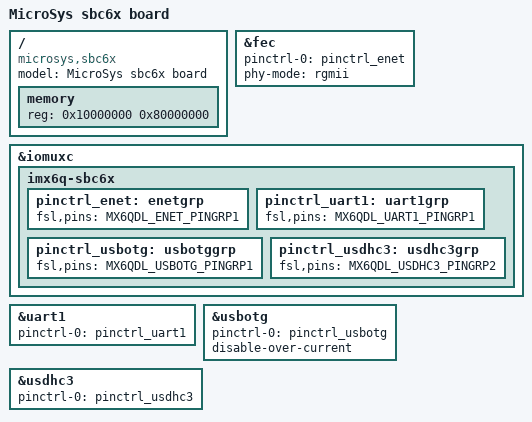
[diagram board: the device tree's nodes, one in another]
/*
 * Copyright 2013 Pavel Machek <pavel@denx.de>
 *
 * The code contained herein is licensed under the GNU General Public
 * License V2.
 */

/dts-v1/;
#include "imx6q.dtsi"

/ {
	model = "MicroSys sbc6x board";
	compatible = "microsys,sbc6x", "fsl,imx6q";

	memory {
		reg = <0x10000000 0x80000000>;
	};
};


&fec {
	pinctrl-names = "default";
	pinctrl-0 = <&pinctrl_enet>;
	phy-mode = "rgmii";
	status = "okay";
};

&iomuxc {
	imx6q-sbc6x {
		pinctrl_enet: enetgrp {
			fsl,pins = <MX6QDL_ENET_PINGRP1>;
		};

		pinctrl_uart1: uart1grp {
			fsl,pins = <MX6QDL_UART1_PINGRP1>;
		};

		pinctrl_usbotg: usbotggrp {
			fsl,pins = <MX6QDL_USBOTG_PINGRP1>;
		};

		pinctrl_usdhc3: usdhc3grp {
			fsl,pins = <MX6QDL_USDHC3_PINGRP2>;
		};
	};
};

&uart1 {
	pinctrl-names = "default";
	pinctrl-0 = <&pinctrl_uart1>;
	status = "okay";
};

&usbotg {
	pinctrl-names = "default";
	pinctrl-0 = <&pinctrl_usbotg>;
	disable-over-current;
	status = "okay";
};

&usdhc3 {
	pinctrl-names = "default";
	pinctrl-0 = <&pinctrl_usdhc3>;
	status = "okay";
};
